# R7FA8M1AH register map
Vendor: Renesas; Series: RA8; File version: 1.2
CPU: CM85 r0p0, little endian, MPU, FPU, VTOR, 4 interrupt priority bits
Registers are 32-bit, read-write, reset 0x0 unless marked. A register's access mark holds for its fields unless they carry their own. Offsets are from the block's base; [hi:lo] are bit positions; {n}, {i} and the like mark numbered series; 'fields as' and 'values as' point back to an identical list; <NAME> marks a mode.

## SCI0 (part 2 of 2) — Serial Communication Interface 0
Base 0x40358000
Same registers: SCI1 0x40358100, SCI2 0x40358200, SCI3 0x40358300, SCI4 0x40358400, SCI9 0x40358900, SCI0_NS 0x50358000, SCI1_NS 0x50358100, SCI2_NS 0x50358200, SCI3_NS 0x50358300, SCI4_NS 0x50358400, SCI9_NS 0x50358900
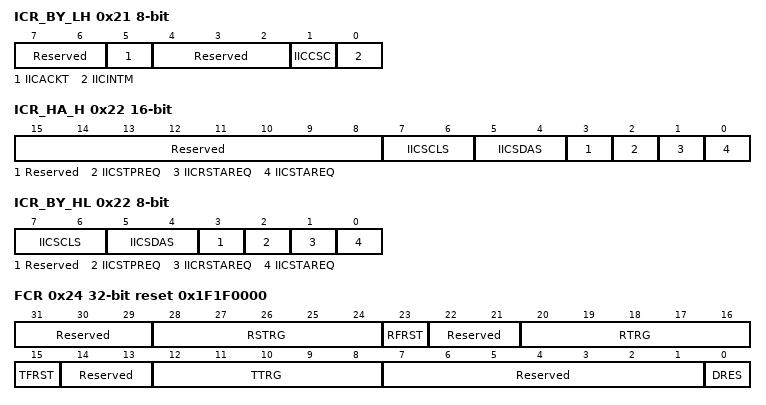
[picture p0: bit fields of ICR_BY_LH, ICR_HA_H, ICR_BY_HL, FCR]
0x21 ICR_BY_LH 8-bit — Simple-I2C Control Register
  [7:6] Reserved — These bits are read as 00. The write value should be 00.
  [5] IICACKT — ACK Transmission Data
    0=ACK transmission; 1=NACK transmission and reception of ACK/NACK
  [4:2] Reserved — These bits are read as 000. The write value should be 000.
  [1] IICCSC — Clock Synchronization
    0=No synchronization with the clock signal; 1=Synchronization with the clock signal
  [0] IICINTM — I2C Interrupt Mode Select
    0=Use ACK/NACK interrupts; 1=Use reception and transmission interrupts
0x22 ICR_HA_H 16-bit — Simple-I2C Control Register
  [15:8] Reserved — These bits are read as 00000000. The write value should be 00000000.
  [7:6] IICSCLS — SCL Output Select
    0=Serial clock output; 1=Generate a start, restart, or stop condition; 2=Output the low level on the SSCLn pin; 3=Place the SSCLn pin in the high-impedance state
  [5:4] IICSDAS — SDA Output Select
    0=Serial data output; 1=Generate a start, restart, or stop condition; 2=Output the low level on the SSDAn pin; 3=Place the SSDAn pin in the high-impedance state
  [3] Reserved — This bit is read as 0. The write value should be 0.
  [2] IICSTPREQ — Stop Condition Generation
    0=A stop condition is not generated; 1=A stop condition is generated
  [1] IICRSTAREQ — Restart Condition Generation
    0=A restart condition is not generated; 1=A restart condition is generated
  [0] IICSTAREQ — Start Condition Generation
    0=A start condition is not generated; 1=A start condition is generated
0x22 ICR_BY_HL 8-bit — Simple-I2C Control Register
  [7:6] IICSCLS — SCL Output Select
    values as ICR_HA_H.IICSCLS
  [5:4] IICSDAS — SDA Output Select
    values as ICR_HA_H.IICSDAS
  [3] Reserved — This bit is read as 0. The write value should be 0.
  [2] IICSTPREQ — Stop Condition Generation
    values as ICR_HA_H.IICSTPREQ
  [1] IICRSTAREQ — Restart Condition Generation
    values as ICR_HA_H.IICRSTAREQ
  [0] IICSTAREQ — Start Condition Generation
    values as ICR_HA_H.IICSTAREQ
0x24 FCR reset 0x1F1F0000 — FIFO Control Register
  [31:29] Reserved — These bits are read as 000. The write value should be 000.
  [28:24] RSTRG — RTS# Output ActiveTrigger Number Select
  [23] RFRST wo — Receive FIFO Data Register Reset
    0=The number of data stored in RDR register are NOT made "0"; 1=The number of data stored in RDR register are made "0"
  [22:21] Reserved — These bits are read as 00. The write value should be 00.
  [20:16] RTRG — Receive FIFO data trigger number
  [15] TFRST wo — Transmit FIFO Data Register Reset
    0=The number of data stored in TDR register are NOT made "0"; 1=The number of data stored in TDR register are made "0"
  [14:13] Reserved — These bits are read as 00. The write value should be 00.
  [12:8] TTRG — Transmit FIFO data trigger number
  [7:1] Reserved — These bits are read as 0000000. The write value should be 0000000.
  [0] DRES — Receive data ready error select bit
    0=reception data full interrupt (RXI); 1=receive error interrupt (ERI)
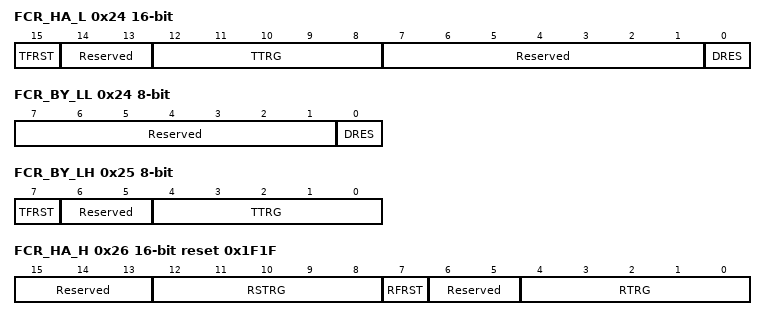
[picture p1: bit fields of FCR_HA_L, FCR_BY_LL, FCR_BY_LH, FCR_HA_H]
0x24 FCR_HA_L 16-bit — FIFO Control Register
  [15] TFRST wo — Transmit FIFO Data Register Reset
    values as FCR.TFRST
  [14:13] Reserved — These bits are read as 00. The write value should be 00.
  [12:8] TTRG — Transmit FIFO data trigger number
  [7:1] Reserved — These bits are read as 0000000. The write value should be 0000000.
  [0] DRES — Receive data ready error select bit
    values as FCR.DRES
0x24 FCR_BY_LL 8-bit — FIFO Control Register
  [7:1] Reserved — These bits are read as 0000000. The write value should be 0000000.
  [0] DRES — Receive data ready error select bit
    values as FCR.DRES
0x25 FCR_BY_LH 8-bit — FIFO Control Register
  [7] TFRST wo — Transmit FIFO Data Register Reset
    values as FCR.TFRST
  [6:5] Reserved — These bits are read as 00. The write value should be 00.
  [4:0] TTRG — Transmit FIFO data trigger number
0x26 FCR_HA_H 16-bit reset 0x1F1F — FIFO Control Register
  [15:13] Reserved — These bits are read as 000. The write value should be 000.
  [12:8] RSTRG — RTS# Output ActiveTrigger Number Select
  [7] RFRST wo — Receive FIFO Data Register Reset
    values as FCR.RFRST
  [6:5] Reserved — These bits are read as 00. The write value should be 00.
  [4:0] RTRG — Receive FIFO data trigger number
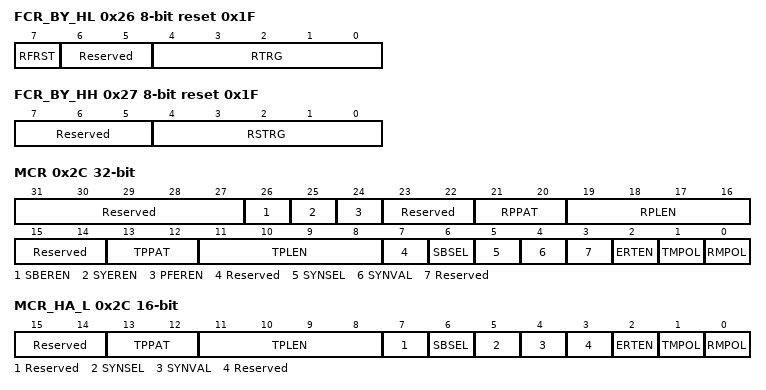
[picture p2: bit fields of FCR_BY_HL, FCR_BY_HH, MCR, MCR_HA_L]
0x26 FCR_BY_HL 8-bit reset 0x1F — FIFO Control Register
  [7] RFRST wo — Receive FIFO Data Register Reset
    values as FCR.RFRST
  [6:5] Reserved — These bits are read as 00. The write value should be 00.
  [4:0] RTRG — Receive FIFO data trigger number
0x27 FCR_BY_HH 8-bit reset 0x1F — FIFO Control Register
  [7:5] Reserved — These bits are read as 000. The write value should be 000.
  [4:0] RSTRG — RTS# Output ActiveTrigger Number Select
0x2C MCR — Manchester Control Register
  [31:27] Reserved — These bits are read as 00000. The write value should be 00000.
  [26] SBEREN — Start bit error enable
    0=Not handle start bit error as interrupt; 1=Handle start bit error as interrupt
  [25] SYEREN — Sync Error enable
    0=Not handle recive sync error as interrupt; 1=Handle receive sync error as interrupt
  [24] PFEREN — Preface Error enable
    0=Not handle preface error as interrupt; 1=Handle preface error as interrupt
  [23:22] Reserved — These bits are read as 00. The write value should be 00.
  [21:20] RPPAT — Receive preface pattern
    0=ALL ZERO; 1=ZERO ONE; 2=ONE ZERO; 3=ALL ONE
  [19:16] RPLEN — Receive preface length
    0=Receive preface generation disabled; other=others (Receive preface length (bit length).)
  [15:14] Reserved — These bits are read as 00. The write value should be 00.
  [13:12] TPPAT — Transmit preface pattern.
    0=ALL ZERO; 1=ZERO ONE
  [11:8] TPLEN — Transmit preface length.
    0=Transmit preface generation disabled; other=others (Transmission preface length (bit length).)
  [7] Reserved — This bit is read as 0. The write value should be 0.
  [6] SBSEL — Start bit select
    0=Start bit is 1 bit; 1=Start bit is Command Sync / Data Sync (3 bits)
  [5] SYNSEL — Sync select
    0=Sync type is set with the SYNVAL bit; 1=Sync type is set by TSYNC bit
  [4] SYNVAL — Sync type of Manchester code start bit is set.
    0=Start bit is added as <0 → 1 transition> with 1 bit.(SBSEL=0 Transmission )/ Receive only when the start bit is 1 bit <0 → 1 transition> pattern,Otherwise it is judged as an error.(SBSEL=0 Receive)/Start bit is added as <0 → 1 transition> with 3 bits(SBSEL=1 Transmission); 1=Start bit is added as <1 → 0 transition> with 1 bit.(SBSEL=0 Transmission )/ Receive only when the start bit is 1 bit <1 → 0 transition> pattern.Otherwise it is judged as an error.(SEBSEL=0,Receive)/ Start bit is added as <1 → 0 transition> with 3 bits(SBSEL=1 Transmission)
  [3] Reserved — This bit is read as 0. The write value should be 0.
  [2] ERTEN — Manchester edge retiming enable
    0=Disables the receive retiming function; 1=Enable the receive retiming function
  [1] TMPOL — Transmission Manchester polarity
    0=Logic code 0 is changed from 0 to 1 of Manchester code.Logic code 1 is changed from 1 to 0 of Manchester code; 1=Logic code 0 is changed from 1 to 0 of Manchester code.Logic code 1 is changed from 0 to 1 of Manchester code
  [0] RMPOL — Receive Manchester polarity
    0=Logic code 0 is changed from 0 to 1 of Manchester code. Logic code 1 is changed from 1 to 0 of Manchester code.; 1=Logic code 0 is changed from 1 to 0 of Manchester code. Logic code 1 is changed from 0 to 1 of Manchester code.
0x2C MCR_HA_L 16-bit — Manchester Control Register
  [15:14] Reserved — These bits are read as 00. The write value should be 00.
  [13:12] TPPAT — Transmit preface pattern.
    0=ALL ZERO; 1=ZERO ONE
  [11:8] TPLEN — Transmit preface length.
    values as MCR.TPLEN
  [7] Reserved — This bit is read as 0. The write value should be 0.
  [6] SBSEL — Start bit select
    values as MCR.SBSEL
  [5] SYNSEL — Sync select
    values as MCR.SYNSEL
  [4] SYNVAL — Sync type of Manchester code start bit is set.
    values as MCR.SYNVAL
  [3] Reserved — This bit is read as 0. The write value should be 0.
  [2] ERTEN — Manchester edge retiming enable
    values as MCR.ERTEN
  [1] TMPOL — Transmission Manchester polarity
    values as MCR.TMPOL
  [0] RMPOL — Receive Manchester polarity
    values as MCR.RMPOL
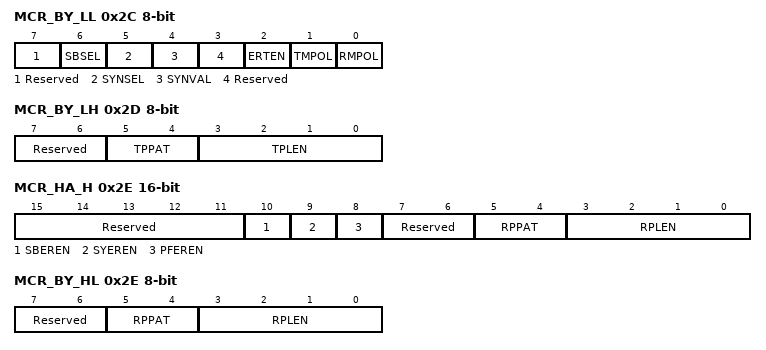
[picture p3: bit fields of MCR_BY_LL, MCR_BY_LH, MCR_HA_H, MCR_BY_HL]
0x2C MCR_BY_LL 8-bit — Manchester Control Register
  [7] Reserved — This bit is read as 0. The write value should be 0.
  [6] SBSEL — Start bit select
    values as MCR.SBSEL
  [5] SYNSEL — Sync select
    values as MCR.SYNSEL
  [4] SYNVAL — Sync type of Manchester code start bit is set.
    values as MCR.SYNVAL
  [3] Reserved — This bit is read as 0. The write value should be 0.
  [2] ERTEN — Manchester edge retiming enable
    values as MCR.ERTEN
  [1] TMPOL — Transmission Manchester polarity
    values as MCR.TMPOL
  [0] RMPOL — Receive Manchester polarity
    values as MCR.RMPOL
0x2D MCR_BY_LH 8-bit — Manchester Control Register
  [7:6] Reserved — These bits are read as 00. The write value should be 00.
  [5:4] TPPAT — Transmit preface pattern.
    0=ALL ZERO; 1=ZERO ONE
  [3:0] TPLEN — Transmit preface length.
    values as MCR.TPLEN
0x2E MCR_HA_H 16-bit — Manchester Control Register
  [15:11] Reserved — These bits are read as 00000. The write value should be 00000.
  [10] SBEREN — Start bit error enable
    values as MCR.SBEREN
  [9] SYEREN — Sync Error enable
    values as MCR.SYEREN
  [8] PFEREN — Preface Error enable
    values as MCR.PFEREN
  [7:6] Reserved — These bits are read as 00. The write value should be 00.
  [5:4] RPPAT — Receive preface pattern
    0=ALL ZERO; 1=ZERO ONE; 2=ONE ZERO; 3=ALL ONE
  [3:0] RPLEN — Receive preface length
    values as MCR.RPLEN
0x2E MCR_BY_HL 8-bit — Manchester Control Register
  [7:6] Reserved — These bits are read as 00. The write value should be 00.
  [5:4] RPPAT — Receive preface pattern
    0=ALL ZERO; 1=ZERO ONE; 2=ONE ZERO; 3=ALL ONE
  [3:0] RPLEN — Receive preface length
    values as MCR.RPLEN
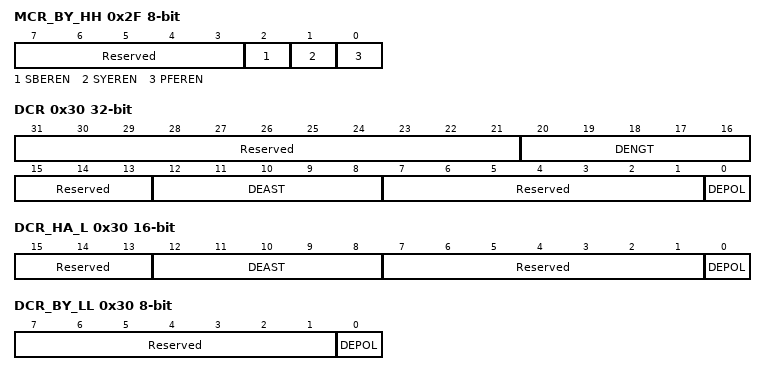
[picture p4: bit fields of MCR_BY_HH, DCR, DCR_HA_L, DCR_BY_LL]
0x2F MCR_BY_HH 8-bit — Manchester Control Register
  [7:3] Reserved — These bits are read as 00000. The write value should be 00000.
  [2] SBEREN — Start bit error enable
    values as MCR.SBEREN
  [1] SYEREN — Sync Error enable
    values as MCR.SYEREN
  [0] PFEREN — Preface Error enable
    values as MCR.PFEREN
0x30 DCR — Driver Control Register
  [31:21] Reserved — These bits are read as 00000000000. The write value should be 00000000000.
  [20:16] DENGT — Deriver Enable NeGate Time
  [15:13] Reserved — These bits are read as 000. The write value should be 000.
  [12:8] DEAST — Driver Enable Assertion Time
  [7:1] Reserved — These bits are read as 0000000. The write value should be 0000000.
  [0] DEPOL — Driver Enable POLarity select
    0=Driver enable signal is active high; 1=Driver enable signal is active low
0x30 DCR_HA_L 16-bit — Driver Control Register
  [15:13] Reserved — These bits are read as 000. The write value should be 000.
  [12:8] DEAST — Driver Enable Assertion Time
  [7:1] Reserved — These bits are read as 0000000. The write value should be 0000000.
  [0] DEPOL — Driver Enable POLarity select
    values as DCR.DEPOL
0x30 DCR_BY_LL 8-bit — Driver Control Register
  [7:1] Reserved — These bits are read as 0000000. The write value should be 0000000.
  [0] DEPOL — Driver Enable POLarity select
    values as DCR.DEPOL
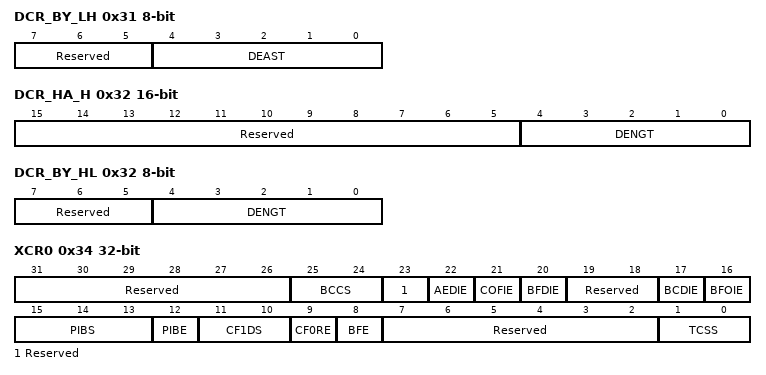
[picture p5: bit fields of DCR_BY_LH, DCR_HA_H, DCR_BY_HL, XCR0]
0x31 DCR_BY_LH 8-bit — Driver Control Register
  [7:5] Reserved — These bits are read as 000. The write value should be 000.
  [4:0] DEAST — Driver Enable Assertion Time
0x32 DCR_HA_H 16-bit — Driver Control Register
  [15:5] Reserved — These bits are read as 00000000000. The write value should be 00000000000.
  [4:0] DENGT — Deriver Enable NeGate Time
0x32 DCR_BY_HL 8-bit — Driver Control Register
  [7:5] Reserved — These bits are read as 000. The write value should be 000.
  [4:0] DENGT — Deriver Enable NeGate Time
0x34 XCR0 — Simple-LIN(SCIX) Control Register 0
  [31:26] Reserved — These bits are read as 000000. The write value should be 000000.
  [25:24] BCCS — Bus Collision detection Clock Select
    0=RSCI base clock; 1=RSCI base clock/2; 2=RSCI base clock/4; 3=Prohibit
  [23] Reserved — This bit is read as 0. The write value should be 0.
  [22] AEDIE — Active Edge Detection Interrupt Enable
    0=Active edge detection interrupt is disable; 1=Active edge detection interrupt is enable
  [21] COFIE — Counter Over Flow Interrupt Enable
    0=Counter over flow is not a factor of ERI; 1=Counter over flow is a factor of ERI
  [20] BFDIE — Break Filed Detection Interrupt Enable
    0=Break field detection interrupt is disable; 1=Break field detection interrupt is enable
  [19:18] Reserved — These bits are read as 00. The write value should be 00.
  [17] BCDIE — Bus Collision Detect Interrupt Enable
    0=Bus collision detection is not a factor of ERI; 1=Bus collision detection is a factor of ERI
  [16] BFOIE — Break Filed Output end Interrupt Enable
    0=Break field output end is not a factor of TXI; 1=Break field output end is a factor of TXI
  [15:13] PIBS — Priority Interrupt Bit select
    {v}=Control Field 1, bit {v} (v=0..7)
  [12] PIBE — Priority Interrupt Bit Enable
    0=Priority interrupt bit is disable; 1=Priority interrupt bit is enable
  [11:10] CF1DS — Control field 1 compare data select
    0=XCR1.PCF1D[7:0] is compare data; 1=XCR1.SCF1D[7:0] is compare data; 2=XCR1.PCF1D[7:0] and XCR1.SCF1D[7:0] are compare data; 3=Prohibit
  [9] CF0RE — Control field 0 presence/absence select
    0=Control field 0 exists in Start frame; 1=No Control field 0 in Start frame
  [8] BFE — Break field presence/absence select
    0=Break field exists in Start frame; 1=No break field in Start frame
  [7:2] Reserved — These bits are read as 000000. The write value should be 000000.
  [1:0] TCSS — Timer count clock source select
    0=TCLK; 1=TCLK/4; 2=TCLK/16; 3=TCLK/64
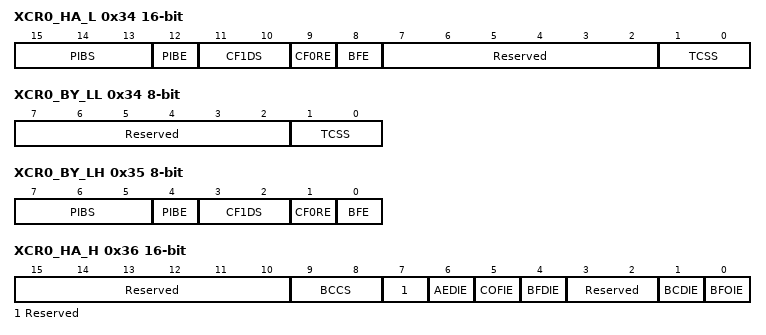
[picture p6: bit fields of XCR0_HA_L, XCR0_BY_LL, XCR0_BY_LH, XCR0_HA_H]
0x34 XCR0_HA_L 16-bit — Simple-LIN(SCIX) Control Register 0
  [15:13] PIBS — Priority Interrupt Bit select
    {v}=Control Field 1, bit {v} (v=0..7)
  [12] PIBE — Priority Interrupt Bit Enable
    values as XCR0.PIBE
  [11:10] CF1DS — Control field 1 compare data select
    values as XCR0.CF1DS
  [9] CF0RE — Control field 0 presence/absence select
    values as XCR0.CF0RE
  [8] BFE — Break field presence/absence select
    values as XCR0.BFE
  [7:2] Reserved — These bits are read as 000000. The write value should be 000000.
  [1:0] TCSS — Timer count clock source select
    0=TCLK; 1=TCLK/4; 2=TCLK/16; 3=TCLK/64
0x34 XCR0_BY_LL 8-bit — Simple-LIN(SCIX) Control Register 0
  [7:2] Reserved — These bits are read as 000000. The write value should be 000000.
  [1:0] TCSS — Timer count clock source select
    0=TCLK; 1=TCLK/4; 2=TCLK/16; 3=TCLK/64
0x35 XCR0_BY_LH 8-bit — Simple-LIN(SCIX) Control Register 0
  [7:5] PIBS — Priority Interrupt Bit select
    {v}=Control Field 1, bit {v} (v=0..7)
  [4] PIBE — Priority Interrupt Bit Enable
    values as XCR0.PIBE
  [3:2] CF1DS — Control field 1 compare data select
    values as XCR0.CF1DS
  [1] CF0RE — Control field 0 presence/absence select
    values as XCR0.CF0RE
  [0] BFE — Break field presence/absence select
    values as XCR0.BFE
0x36 XCR0_HA_H 16-bit — Simple-LIN(SCIX) Control Register 0
  [15:10] Reserved — These bits are read as 000000. The write value should be 000000.
  [9:8] BCCS — Bus Collision detection Clock Select
    values as XCR0.BCCS
  [7] Reserved — This bit is read as 0. The write value should be 0.
  [6] AEDIE — Active Edge Detection Interrupt Enable
    values as XCR0.AEDIE
  [5] COFIE — Counter Over Flow Interrupt Enable
    values as XCR0.COFIE
  [4] BFDIE — Break Filed Detection Interrupt Enable
    values as XCR0.BFDIE
  [3:2] Reserved — These bits are read as 00. The write value should be 00.
  [1] BCDIE — Bus Collision Detect Interrupt Enable
    values as XCR0.BCDIE
  [0] BFOIE — Break Filed Output end Interrupt Enable
    values as XCR0.BFOIE
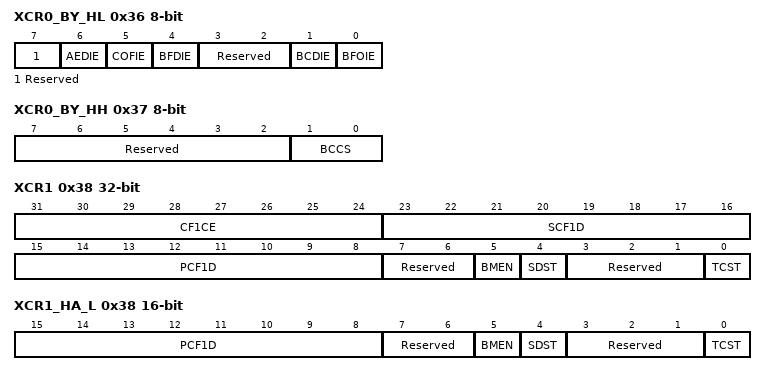
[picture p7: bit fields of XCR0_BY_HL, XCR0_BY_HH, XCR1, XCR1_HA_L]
0x36 XCR0_BY_HL 8-bit — Simple-LIN(SCIX) Control Register 0
  [7] Reserved — This bit is read as 0. The write value should be 0.
  [6] AEDIE — Active Edge Detection Interrupt Enable
    values as XCR0.AEDIE
  [5] COFIE — Counter Over Flow Interrupt Enable
    values as XCR0.COFIE
  [4] BFDIE — Break Filed Detection Interrupt Enable
    values as XCR0.BFDIE
  [3:2] Reserved — These bits are read as 00. The write value should be 00.
  [1] BCDIE — Bus Collision Detect Interrupt Enable
    values as XCR0.BCDIE
  [0] BFOIE — Break Filed Output end Interrupt Enable
    values as XCR0.BFOIE
0x37 XCR0_BY_HH 8-bit — Simple-LIN(SCIX) Control Register 0
  [7:2] Reserved — These bits are read as 000000. The write value should be 000000.
  [1:0] BCCS — Bus Collision detection Clock Select
    values as XCR0.BCCS
0x38 XCR1 — Simple-LIN(SCIX) Control Register 1
  [31:24] CF1CE — Control Field 1 Compare bit Enable
    0=Bit N of control Field 1 is not for comparison; 1=Bit N of control Field 1 is for comparison
  [23:16] SCF1D — Secondary compare Data for Control Field 1
  [15:8] PCF1D — Priority compare Data for Control Field 1
  [7:6] Reserved — These bits are read as 00. The write value should be 00.
  [5] BMEN — Bit rate Measurement function Enable
    0=Bit rate Measurement function disable; 1=Bit rate Measurement function enable
  [4] SDST — Start frame Detection Start trigger
    0=Start frame / Break field detetion disable; 1=Start frame / Break field detetion enable
  [3:1] Reserved — These bits are read as 000. The write value should be 000.
  [0] TCST — break field Timer Count Start trigger
    0=Timer count abort for break field output; 1=Timer count start for break field output
0x38 XCR1_HA_L 16-bit — Simple-LIN(SCIX) Control Register 1
  [15:8] PCF1D — Priority compare Data for Control Field 1
  [7:6] Reserved — These bits are read as 00. The write value should be 00.
  [5] BMEN — Bit rate Measurement function Enable
    values as XCR1.BMEN
  [4] SDST — Start frame Detection Start trigger
    values as XCR1.SDST
  [3:1] Reserved — These bits are read as 000. The write value should be 000.
  [0] TCST — break field Timer Count Start trigger
    values as XCR1.TCST
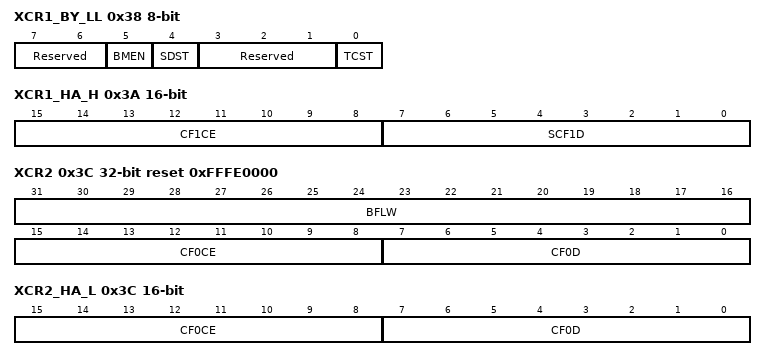
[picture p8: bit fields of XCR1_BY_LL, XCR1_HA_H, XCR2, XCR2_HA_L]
0x38 XCR1_BY_LL 8-bit — Simple-LIN(SCIX) Control Register 1
  [7:6] Reserved — These bits are read as 00. The write value should be 00.
  [5] BMEN — Bit rate Measurement function Enable
    values as XCR1.BMEN
  [4] SDST — Start frame Detection Start trigger
    values as XCR1.SDST
  [3:1] Reserved — These bits are read as 000. The write value should be 000.
  [0] TCST — break field Timer Count Start trigger
    values as XCR1.TCST
0x39 XCR1_BY_LH 8-bit — Simple-LIN(SCIX) Control Register 1
  [7:0] PCF1D — Priority compare Data for Control Field 1
0x3A XCR1_HA_H 16-bit — Simple-LIN(SCIX) Control Register 1
  [15:8] CF1CE — Control Field 1 Compare bit Enable
    values as XCR1.CF1CE
  [7:0] SCF1D — Secondary compare Data for Control Field 1
0x3A XCR1_BY_HL 8-bit — Simple-LIN(SCIX) Control Register 1
  [7:0] SCF1D — Secondary compare Data for Control Field 1
0x3B XCR1_BY_HH 8-bit — Simple-LIN(SCIX) Control Register 1
  [7:0] CF1CE — Control Field 1 Compare bit Enable
    values as XCR1.CF1CE
0x3C XCR2 reset 0xFFFE0000 — Simple-LIN(SCIX) Control Register 2
  [31:16] BFLW — Break Field Low Width
  [15:8] CF0CE — Control Field 0 Compare bit Enable
    0=Bit N of control Field 0 is not for comparison; 1=Bit N of control Field 0 is for comparison
  [7:0] CF0D — Compare Data for Control Field 0
0x3C XCR2_HA_L 16-bit — Simple-LIN(SCIX) Control Register 2
  [15:8] CF0CE — Control Field 0 Compare bit Enable
    values as XCR2.CF0CE
  [7:0] CF0D — Compare Data for Control Field 0
0x3C XCR2_BY_LL 8-bit — Simple-LIN(SCIX) Control Register 2
  [7:0] CF0D — Compare Data for Control Field 0
0x3D XCR2_BY_LH 8-bit — Simple-LIN(SCIX) Control Register 2
  [7:0] CF0CE — Control Field 0 Compare bit Enable
    values as XCR2.CF0CE
0x3E XCR2_HA_H 16-bit reset 0xFFFE — Simple-LIN(SCIX) Control Register 2
  [15:0] BFLW — Break Field Low Width
0x3E XCR2_BY_HL 8-bit reset 0xFE — Simple-LIN(SCIX) Control Register 2
  [7:0] BFLW — Break Field Low Width
0x3F XCR2_BY_HH 8-bit reset 0xFF — Simple-LIN(SCIX) Control Register 2
  [7:0] BFLW — Break Field Low Width
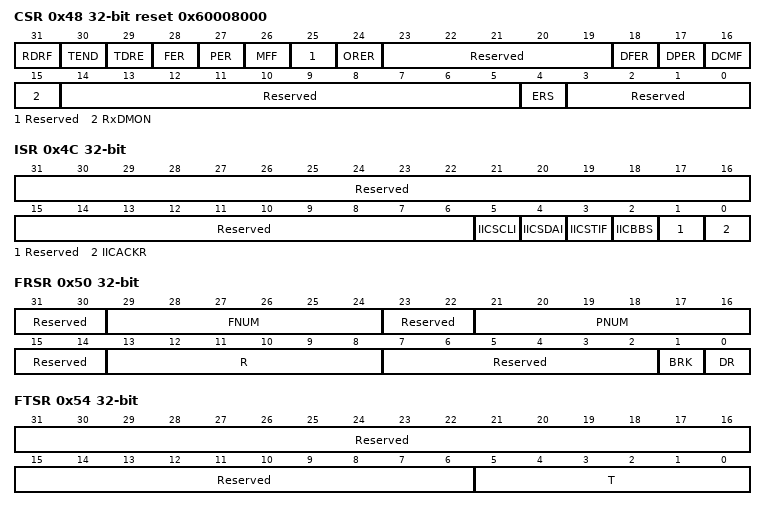
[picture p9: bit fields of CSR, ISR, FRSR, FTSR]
0x48 CSR ro reset 0x60008000 — Common Status Register
  [31] RDRF — Receive Data Full Flag
    0=No received data is in RDR register; 1=Received data is in RDR register
  [30] TEND — Transmit End Flag
    0=A character is being transmitted; 1=Character transfer has been completed
  [29] TDRE — Transmit Data Empty Flag
    0=Transmit data is in TDR register; 1=No transmit data is in TDR register
  [28] FER — Framing Error Flag
    0=No framing error occurred; 1=A framing error has occurred
  [27] PER — Parity Error Flag
    0=No parity error occurred; 1=A parity error has occurred
  [26] MFF — Mode Fault Flag
    0=No mode fault error; 1=Mode fault error
  [25] Reserved — This bit is read as 0.
  [24] ORER — Overrun Error Flag
    0=No overrun error occurred; 1=An overrun error has occurred
  [23:19] Reserved — These bits are read as 00000.
  [18] DFER — Data Compare Match Framing Error Flag
    0=No framing error occurred; 1=A framing error has occurred
  [17] DPER — Data Compare Match Parity Error Flag
    0=No parity error occurred; 1=A parity error has occurred
  [16] DCMF — Data Compare Match Flag
    0=No matched; 1=Matched
  [15] RxDMON — Serial input data monitor bit
    0=RXD terminal is the Low level, when RINV is 0; 1=RXD terminal is the High level, when RINV is 1
  [14:5] Reserved — These bits are read as 0000000000.
  [4] ERS — Error Signal Status Flag
    0=Low error signal not responded; 1=Low error signal responded
  [3:0] Reserved — These bits are read as 0000.
0x4C ISR ro — Simple-I2C Status Register
  [31:6] Reserved — These bits are read as 00000000000000000000000000.
  [5] IICSCLI — SCL input monitor bit
    0=SCL pin state is low level; 1=SCL pin state is high level
  [4] IICSDAI — SDA input monitor bit.
    0=SDA pin state is low level; 1=SDA pin state is high level
  [3] IICSTIF — Issuing of Start, Restart, or Stop Condition Completed Flag
    0=There are no requests for generating conditions or a condition is being generated; 1=A start, restart, or stop condition is completely generated
  [2] IICBBS — Bus busy flag.
    0=Stop condition detection; 1=Start condition detection
  [1] Reserved — This bit is read as 0.
  [0] IICACKR — ACK Reception Data Flag
    0=ACK received; 1=NACK received
0x50 FRSR ro — FIFO Receive Status Register
  [31:30] Reserved — These bits are read as 00.
  [29:24] FNUM — Framing Error Count
  [23:22] Reserved — These bits are read as 00.
  [21:16] PNUM — Parity Error Count
  [15:14] Reserved — These bits are read as 00.
  [13:8] R — Receive FIFO Data Count
  [7:2] Reserved — These bits are read as 000000.
  [1] BRK — Break detection signal flag
    0=No break signal is received; 1=A break signal is received
  [0] DR — Receive Data Ready flag
    0=Receiving is in progress, or no received data has remained in RDR after normally completed receiving.(receive FIFO is empty); 1=Next receive data has not been received for a fixed period after normal completed receiving
0x54 FTSR ro — FIFO Transmit Status Register
  [31:6] Reserved — These bits are read as 00000000000000000000000000.
  [5:0] T — Transmit FIFO Data Count
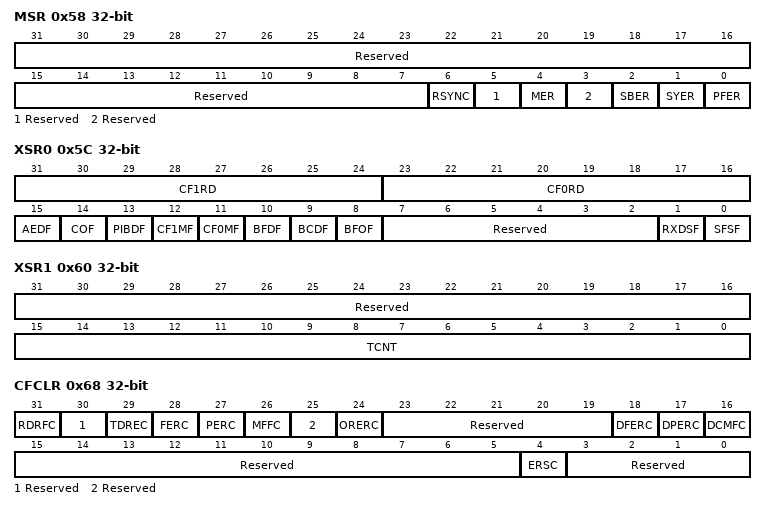
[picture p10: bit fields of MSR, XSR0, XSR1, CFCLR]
0x58 MSR ro — Manchester Status Register
  [31:7] Reserved — These bits are read as 0000000000000000000000000.
  [6] RSYNC — Receive sync data bit.
    0=Start bit receives data Sync; 1=Start bit receives command Sync
  [5] Reserved — This bit is read as 0.
  [4] MER — Manchester error flag
    0=No Manchester error occurred; 1=A manchester error has occurred
  [3] Reserved — This bit is read as 0.
  [2] SBER — Start bit Error Register
    0=No start bit error detected; 1=Start bit error detected
  [1] SYER — Sync Error Registe
    0=Receive sync error not detected; 1=Receive sync error detected
  [0] PFER — Preface Error Register
    0=No prefetch error detected; 1=Prefetch error detected
0x5C XSR0 ro — Simple-LIN(SCIX) Status Register 0
  [31:24] CF1RD — Control Field 1 Read Data
  [23:16] CF0RD — Control Field 0 Read Data
  [15] AEDF — Active Edge Detection Flag
  [14] COF — Counter Over flow Flag
  [13] PIBDF — Priority Interrupt Bit Detection Flag
  [12] CF1MF — Control Field 1 Match Flag
  [11] CF0MF — Control Field 0 Match Flag
  [10] BFDF — Break Field Detection Flag
  [9] BCDF — Bus Collision Detection Flag
  [8] BFOF — Break Field Output end Flag
  [7:2] Reserved — These bits are read as 000000.
  [1] RXDSF — RXD input Status Flag
    0=Permit RXD input to core; 1=Prohibit RXD input to core
  [0] SFSF — Start Frame Status Flag
    values as XCR1.SDST
0x60 XSR1 ro — Simple-LIN(SCIX) Status Register 1
  [31:16] Reserved — These bits are read as 0000000000000000.
  [15:0] TCNT — Timer CouNT capture value
0x68 CFCLR wo — Common Flag Clear Register
  [31] RDRFC — RDRF Clear bit
  [30] Reserved — The write value should be 0.
  [29] TDREC — TDRE Clear bit
  [28] FERC — FER Clear bit
  [27] PERC — PER Clear bit
  [26] MFFC — MFF Clear bit
  [25] Reserved — The write value should be 0.
  [24] ORERC — ORER Clear bit
  [23:19] Reserved — The write value should be 00000.
  [18] DFERC — DFER Clear bit
  [17] DPERC — DPER Clear bit
  [16] DCMFC — DCMF Clear bit
  [15:5] Reserved — The write value should be 00000000000.
  [4] ERSC — ERS Clear bit
  [3:0] Reserved — The write value should be 0000.
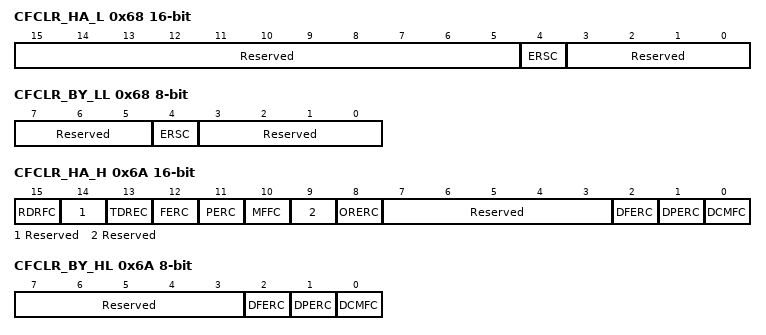
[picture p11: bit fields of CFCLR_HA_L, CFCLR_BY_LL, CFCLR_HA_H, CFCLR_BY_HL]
0x68 CFCLR_HA_L 16-bit wo — Common Flag Clear Register
  [15:5] Reserved — The write value should be 00000000000.
  [4] ERSC — ERS Clear bit
  [3:0] Reserved — The write value should be 0000.
0x68 CFCLR_BY_LL 8-bit wo — Common Flag Clear Register
  [7:5] Reserved — The write value should be 000.
  [4] ERSC — ERS Clear bit
  [3:0] Reserved — The write value should be 0000.
0x6A CFCLR_HA_H 16-bit wo — Common Flag Clear Register
  [15] RDRFC — RDRF Clear bit
  [14] Reserved — The write value should be 0.
  [13] TDREC — TDRE Clear bit
  [12] FERC — FER Clear bit
  [11] PERC — PER Clear bit
  [10] MFFC — MFF Clear bit
  [9] Reserved — The write value should be 0.
  [8] ORERC — ORER Clear bit
  [7:3] Reserved — The write value should be 00000.
  [2] DFERC — DFER Clear bit
  [1] DPERC — DPER Clear bit
  [0] DCMFC — DCMF Clear bit
0x6A CFCLR_BY_HL 8-bit wo — Common Flag Clear Register
  [7:3] Reserved — The write value should be 00000.
  [2] DFERC — DFER Clear bit
  [1] DPERC — DPER Clear bit
  [0] DCMFC — DCMF Clear bit
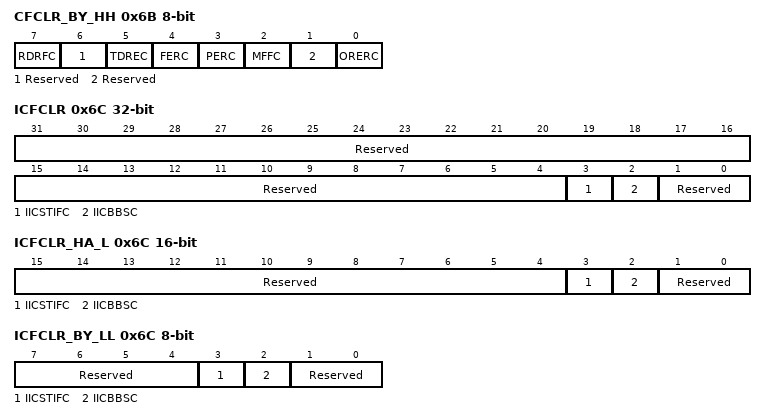
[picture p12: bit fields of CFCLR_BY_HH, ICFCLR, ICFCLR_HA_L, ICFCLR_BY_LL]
0x6B CFCLR_BY_HH 8-bit wo — Common Flag Clear Register
  [7] RDRFC — RDRF Clear bit
  [6] Reserved — The write value should be 0.
  [5] TDREC — TDRE Clear bit
  [4] FERC — FER Clear bit
  [3] PERC — PER Clear bit
  [2] MFFC — MFF Clear bit
  [1] Reserved — The write value should be 0.
  [0] ORERC — ORER Clear bit
0x6C ICFCLR wo — Simple-I2C Flag Clear Register
  [31:4] Reserved — The write value should be 0000000000000000000000000000.
  [3] IICSTIFC — IICSTIF Clear bit
  [2] IICBBSC — IICBBS Clear bit
  [1:0] Reserved — The write value should be 00.
0x6C ICFCLR_HA_L 16-bit wo — Simple-I2C Flag Clear Register
  [15:4] Reserved — The write value should be 000000000000.
  [3] IICSTIFC — IICSTIF Clear bit
  [2] IICBBSC — IICBBSC Clear bit
  [1:0] Reserved — The write value should be 00.
0x6C ICFCLR_BY_LL 8-bit wo — Simple-I2C Flag Clear Register
  [7:4] Reserved — The write value should be 0000.
  [3] IICSTIFC — IICSTIF Clear bit
  [2] IICBBSC — IICBBSC Clear bit
  [1:0] Reserved — The write value should be 00.
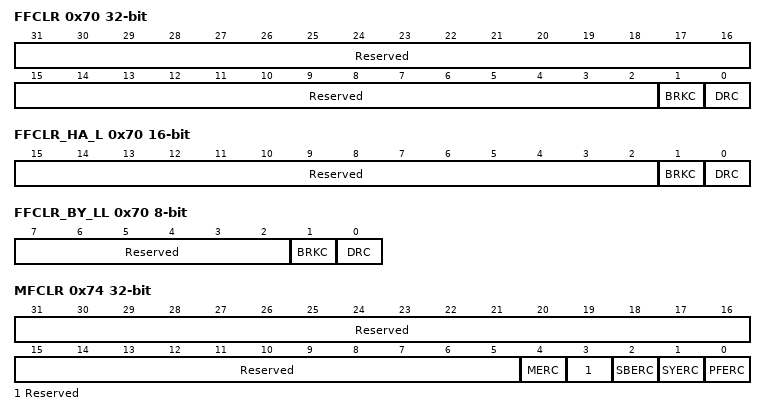
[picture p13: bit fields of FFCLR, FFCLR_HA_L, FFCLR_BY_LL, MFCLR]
0x70 FFCLR wo — FIFO Flag Clear Register
  [31:2] Reserved — The write value should be 000000000000000000000000000000.
  [1] BRKC — BRK Clear bit
  [0] DRC — DR Clear bit
0x70 FFCLR_HA_L 16-bit wo — FIFO Flag Clear Register
  [15:2] Reserved — The write value should be 00000000000000.
  [1] BRKC — BRK Clear bit
  [0] DRC — DR Clear bit
0x70 FFCLR_BY_LL 8-bit wo — FIFO Flag Clear Register
  [7:2] Reserved — The write value should be 000000.
  [1] BRKC — BRK Clear bit
  [0] DRC — DR Clear bit
0x74 MFCLR wo — Manchester Flag Clear Register
  [31:5] Reserved — The write value should be 000000000000000000000000000.
  [4] MERC — MER Clear bit
  [3] Reserved — The write value should be 0.
  [2] SBERC — SBER Clear bit
  [1] SYERC — SYER Clear bit
  [0] PFERC — PFER Clear bit
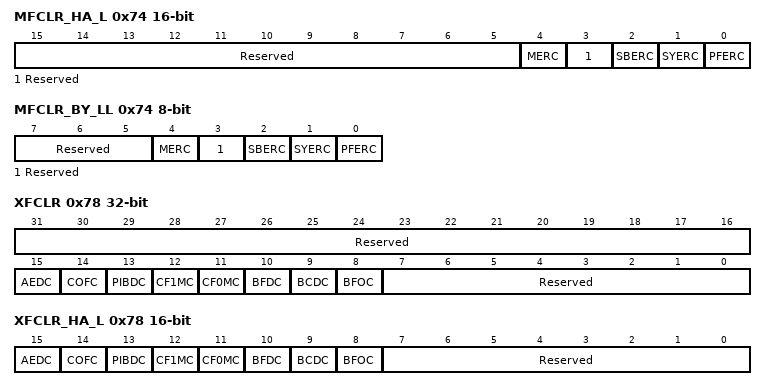
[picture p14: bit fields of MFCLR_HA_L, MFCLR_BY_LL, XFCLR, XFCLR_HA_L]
0x74 MFCLR_HA_L 16-bit wo — Manchester Flag Clear Register
  [15:5] Reserved — The write value should be 00000000000.
  [4] MERC — MER Clear bit
  [3] Reserved — The write value should be 0.
  [2] SBERC — SBER Clear bit
  [1] SYERC — SYER Clear bit
  [0] PFERC — PFER Clear bit
0x74 MFCLR_BY_LL 8-bit wo — Manchester Flag Clear Register
  [7:5] Reserved — The write value should be 000.
  [4] MERC — MER Clear bit
  [3] Reserved — The write value should be 0.
  [2] SBERC — SBER Clear bit
  [1] SYERC — SYER Clear bit
  [0] PFERC — PFER Clear bit
0x78 XFCLR wo — Simpe-LIN(SCIX) Flag Clear Register
  [31:16] Reserved — The write value should be 0000000000000000.
  [15] AEDC — AED Clear bit
  [14] COFC — COF Clear bit
  [13] PIBDC — PIBD Clear bit
  [12] CF1MC — CF1M Clear bit
  [11] CF0MC — CF0M Clear bit
  [10] BFDC — BFD Clear bit
  [9] BCDC — BCD Clear bit
  [8] BFOC — BFO Clear bit
  [7:0] Reserved — The write value should be 00000000.
0x78 XFCLR_HA_L 16-bit wo — Simpe-LIN(SCIX) Flag Clear Register
  [15] AEDC — AED Clear bit
  [14] COFC — COF Clear bit
  [13] PIBDC — PIBD Clear bit
  [12] CF1MC — CF1M Clear bit
  [11] CF0MC — CF0M Clear bit
  [10] BFDC — BFD Clear bit
  [9] BCDC — BCD Clear bit
  [8] BFOC — BFO Clear bit
  [7:0] Reserved — The write value should be 00000000.
0x79 XFCLR_BY_LH 8-bit wo — Simpe-LIN(SCIX) Flag Clear Register
  [7] AEDC — AED Clear bit
  [6] COFC — COF Clear bit
  [5] PIBDC — PIBD Clear bit
  [4] CF1MC — CF1M Clear bit
  [3] CF0MC — CF0M Clear bit
  [2] BFDC — BFD Clear bit
  [1] BCDC — BCD Clear bit
  [0] BFOC — BFO Clear bit
